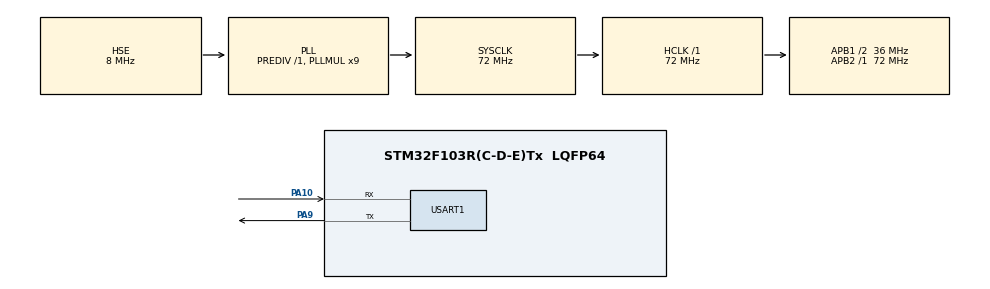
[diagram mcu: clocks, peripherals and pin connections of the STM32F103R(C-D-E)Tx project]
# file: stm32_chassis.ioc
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FREERTOS.Tasks01=defaultTask,24,128,StartDefaultTask,Default,NULL,Dynamic,NULL,NULL
Mcu.Family=STM32F1
Mcu.Name=STM32F103R(C-D-E)Tx
Mcu.Package=LQFP64
NVIC.PriorityGroup=NVIC_PRIORITYGROUP_4
NVIC.TIM1_UP_IRQn=true\:0\:0\:false\:false\:true\:false\:false\:true
NVIC.TimeBase=TIM1_UP_IRQn
NVIC.TimeBaseIP=TIM1
PA10.Mode=Asynchronous
PA10.Signal=USART1_RX
PA13.Mode=Serial_Wire
PA13.Signal=SYS_JTMS-SWDIO
PA14.Mode=Serial_Wire
PA14.Signal=SYS_JTCK-SWCLK
PA9.Mode=Asynchronous
PA9.Signal=USART1_TX
PD0-OSC_IN.Mode=HSE-External-Oscillator
PD0-OSC_IN.Signal=RCC_OSC_IN
PD1-OSC_OUT.Mode=HSE-External-Oscillator
PD1-OSC_OUT.Signal=RCC_OSC_OUT
ProjectManager.HeapSize=0x200
ProjectManager.StackSize=0x400
ProjectManager.TargetToolchain=MDK-ARM V5
RCC.AHBFreq_Value=72000000
RCC.APB1CLKDivider=RCC_HCLK_DIV2
RCC.APB1Freq_Value=36000000
RCC.APB1TimFreq_Value=72000000
RCC.APB2Freq_Value=72000000
RCC.APB2TimFreq_Value=72000000
RCC.HCLKFreq_Value=72000000
RCC.PLLMUL=RCC_PLL_MUL9
RCC.PLLSourceVirtual=RCC_PLLSOURCE_HSE
RCC.SYSCLKFreq_VALUE=72000000
RCC.SYSCLKSource=RCC_SYSCLKSOURCE_PLLCLK
RCC.USBFreq_Value=72000000
USART1.VirtualMode=VM_ASYNC
VP_FREERTOS_VS_CMSIS_V2.Mode=CMSIS_V2
VP_SYS_VS_tim1.Mode=TIM1
board=custom

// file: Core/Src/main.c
/* USER CODE BEGIN Header */
/**
  ******************************************************************************
  * @file           : main.c
  * @brief          : Main program body
  ******************************************************************************
  * @attention
  *
  * <h2><center>&copy; Copyright (c) 2026 STMicroelectronics.
  * All rights reserved.</center></h2>
  *
  * This software component is licensed by ST under Ultimate Liberty license
  * SLA0044, the "License"; You may not use this file except in compliance with
  * the License. You may obtain a copy of the License at:
  *                             www.st.com/SLA0044
  *
  ******************************************************************************
  */
/* USER CODE END Header */
#include "main.h"
#include "cmsis_os.h"
#include "usart.h"
#include "gpio.h"

void SystemClock_Config(void);
void MX_FREERTOS_Init(void);

int main(void)
{

  /* MCU Configuration--------------------------------------------------------*/

  /* Reset of all peripherals, Initializes the Flash interface and the Systick. */
  HAL_Init();

  /* Configure the system clock */
  SystemClock_Config();

  /* Initialize all configured peripherals */
  MX_GPIO_Init();
  MX_USART1_UART_Init();

  /* Init scheduler */
  osKernelInitialize();  /* Call init function for freertos objects (in freertos.c) */
  MX_FREERTOS_Init();
  /* Start scheduler */
  osKernelStart();

  /* We should never get here as control is now taken by the scheduler */
  /* Infinite loop */
  while (1)
  {

  }
}

void SystemClock_Config(void)
{
  RCC_OscInitTypeDef RCC_OscInitStruct = {0};
  RCC_ClkInitTypeDef RCC_ClkInitStruct = {0};

  /** Initializes the RCC Oscillators according to the specified parameters
  * in the RCC_OscInitTypeDef structure.
  */
  RCC_OscInitStruct.OscillatorType = RCC_OSCILLATORTYPE_HSE;
  RCC_OscInitStruct.HSEState = RCC_HSE_ON;
  RCC_OscInitStruct.HSEPredivValue = RCC_HSE_PREDIV_DIV1;
  RCC_OscInitStruct.HSIState = RCC_HSI_ON;
  RCC_OscInitStruct.PLL.PLLState = RCC_PLL_ON;
  RCC_OscInitStruct.PLL.PLLSource = RCC_PLLSOURCE_HSE;
  RCC_OscInitStruct.PLL.PLLMUL = RCC_PLL_MUL9;
  if (HAL_RCC_OscConfig(&RCC_OscInitStruct) != HAL_OK)
  {
    Error_Handler();
  }
  /** Initializes the CPU, AHB and APB buses clocks
  */
  RCC_ClkInitStruct.ClockType = RCC_CLOCKTYPE_HCLK|RCC_CLOCKTYPE_SYSCLK
                              |RCC_CLOCKTYPE_PCLK1|RCC_CLOCKTYPE_PCLK2;
  RCC_ClkInitStruct.SYSCLKSource = RCC_SYSCLKSOURCE_PLLCLK;
  RCC_ClkInitStruct.AHBCLKDivider = RCC_SYSCLK_DIV1;
  RCC_ClkInitStruct.APB1CLKDivider = RCC_HCLK_DIV2;
  RCC_ClkInitStruct.APB2CLKDivider = RCC_HCLK_DIV1;

  if (HAL_RCC_ClockConfig(&RCC_ClkInitStruct, FLASH_LATENCY_2) != HAL_OK)
  {
    Error_Handler();
  }
}

 /**
  * @brief  Period elapsed callback in non blocking mode
  * @note   This function is called  when TIM1 interrupt took place, inside
  * HAL_TIM_IRQHandler(). It makes a direct call to HAL_IncTick() to increment
  * a global variable "uwTick" used as application time base.
  * @param  htim : TIM handle
  * @retval None
  */
void HAL_TIM_PeriodElapsedCallback(TIM_HandleTypeDef *htim)
{
  if (htim->Instance == TIM1) {
    HAL_IncTick();
  }
}

void Error_Handler(void)
{
  __disable_irq();
  while (1)
  {
  }
}

/************************ (C) COPYRIGHT STMicroelectronics *****END OF FILE****/

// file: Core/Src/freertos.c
/* USER CODE BEGIN Header */
/**
  ******************************************************************************
  * File Name          : freertos.c
  * Description        : Code for freertos applications
  ******************************************************************************
  * @attention
  *
  * <h2><center>&copy; Copyright (c) 2026 STMicroelectronics.
  * All rights reserved.</center></h2>
  *
  * This software component is licensed by ST under Ultimate Liberty license
  * SLA0044, the "License"; You may not use this file except in compliance with
  * the License. You may obtain a copy of the License at:
  *                             www.st.com/SLA0044
  *
  ******************************************************************************
  */
/* USER CODE END Header */

#include "FreeRTOS.h"
#include "task.h"
#include "main.h"
#include "cmsis_os.h"

/* USER CODE BEGIN Includes */
#include "chassis_cmd.h"
#include "chassis_motor.h"
#include "chassis_safety.h"
#include "chassis_patrol.h"
/* USER CODE END Includes */

/* Definitions for defaultTask */
osThreadId_t defaultTaskHandle;
const osThreadAttr_t defaultTask_attributes = {
  .name = "defaultTask",
  .stack_size = 256 * 4,
  .priority = (osPriority_t) osPriorityNormal,
};

/* USER CODE BEGIN FunctionPrototypes */
void StartChassisCmdTask(void *argument);
void StartChassisMotorTask(void *argument);
void StartChassisSafetyTask(void *argument);
void StartChassisPatrolTask(void *argument);
/* USER CODE END FunctionPrototypes */

void StartDefaultTask(void *argument);

void MX_FREERTOS_Init(void); /* (MISRA C 2004 rule 8.1) */

void MX_FREERTOS_Init(void) {

  /* Create the thread(s) */
  /* creation of defaultTask */
  defaultTaskHandle = osThreadNew(StartDefaultTask, NULL, &defaultTask_attributes);

  /* USER CODE BEGIN RTOS_THREADS */
  {
    const osThreadAttr_t chassisCmdTask_attributes = {
      .name = "chassisCmd",
      .stack_size = 256 * 4,
      .priority = (osPriority_t) osPriorityNormal,
    };
    osThreadNew(StartChassisCmdTask, NULL, &chassisCmdTask_attributes);
  }
  {
    const osThreadAttr_t chassisMotorTask_attributes = {
      .name = "chassisMotor",
      .stack_size = 256 * 4,
      .priority = (osPriority_t) osPriorityNormal,
    };
    osThreadNew(StartChassisMotorTask, NULL, &chassisMotorTask_attributes);
  }
  {
    const osThreadAttr_t chassisSafetyTask_attributes = {
      .name = "chassisSafety",
      .stack_size = 256 * 4,
      .priority = (osPriority_t) osPriorityAboveNormal,
    };
    osThreadNew(StartChassisSafetyTask, NULL, &chassisSafetyTask_attributes);
  }
  {
    const osThreadAttr_t chassisPatrolTask_attributes = {
      .name = "chassisPatrol",
      .stack_size = 256 * 4,
      .priority = (osPriority_t) osPriorityNormal,
    };
    osThreadNew(StartChassisPatrolTask, NULL, &chassisPatrolTask_attributes);
  }
  /* USER CODE END RTOS_THREADS */

}

void StartDefaultTask(void *argument)
{
  /* USER CODE BEGIN StartDefaultTask */
  for (;;)
  {
    osDelay(1000);
  }
  /* USER CODE END StartDefaultTask */
}

/* USER CODE BEGIN Application */

void StartChassisCmdTask(void *argument)
{
  (void)argument;
  ChassisCmd_Init();
  for (;;)
  {
    ChassisCmd_Poll();
    osDelay(10);
  }
}

void StartChassisMotorTask(void *argument)
{
  (void)argument;
  ChassisMotor_Init();
  for (;;)
  {
    ChassisMotor_Poll();
    osDelay(10);
  }
}

void StartChassisSafetyTask(void *argument)
{
  (void)argument;
  ChassisSafety_Init();
  for (;;)
  {
    ChassisSafety_Poll();
    osDelay(20);
  }
}

void StartChassisPatrolTask(void *argument)
{
  (void)argument;
  ChassisPatrol_Init();
  for (;;)
  {
    ChassisPatrol_Poll();
    osDelay(20);
  }
}

/* USER CODE END Application */

/************************ (C) COPYRIGHT STMicroelectronics *****END OF FILE****/
